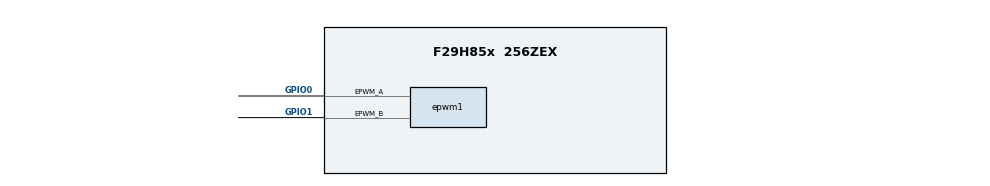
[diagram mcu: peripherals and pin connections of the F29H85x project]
/**
 * @cliArgs --device "F29H85x" --package "256ZEX" --part "F29H85x_256ZEX" --context "CPU1" --product "MCU_SDK_F29H85x@1.02.02.00"
 * @versions {"tool":"1.25.0+4237"}
 */

    
const divider15       = system.clockTree["PLL_REFDIV"];
divider15.divideValue = 1;

const multiplier1         = system.clockTree["PLL_IMULT"];
multiplier1.multiplyValue = 40;

const mux7       = system.clockTree["OSCCLKSRCSEL"];
mux7.inputSelect = "INTOSC2";

/**
 * Import the modules used in this configuration.
 */
const epwm             = scripting.addModule("/driverlib/epwm.js", {}, false);
const epwm1            = epwm.addInstance();
const inputxbar_input  = scripting.addModule("/driverlib/inputxbar_input.js", {}, false);
const inputxbar_input1 = inputxbar_input.addInstance();
const inputxbar_input2 = inputxbar_input.addInstance();

/**
 * Write custom configuration values to the imported modules.
 */
epwm1.$name                  = "myEPWM1";
epwm1.epwm.$assign           = "EPWM1";
epwm1.epwm.epwm_aPin.$assign = "GPIO0";
epwm1.epwm.epwm_bPin.$assign = "GPIO1";
epwm1.periphClock.$name      = "driverlib_perClock0";
epwm1.periphConfig.$name     = "driverlib_perConfig0";

inputxbar_input1.$name          = "myINPUTXBARINPUT0";
inputxbar_input1.inputxbarInput = "XBAR_INPUT5";
inputxbar_input1.inputxbarGpio  = "GPIO40";

inputxbar_input2.$name          = "myINPUTXBARINPUT1";
inputxbar_input2.inputxbarInput = "XBAR_INPUT6";
inputxbar_input2.inputxbarGpio  = "GPIO40";
